# rxflow register map
Vendor: Texas Instruments
Peripheral module from a debugger description file (folder pktdma).
Registers are 32-bit, write-only, no defined reset value unless marked. A register's access mark holds for its fields unless they carry their own. Offsets are as the file gives them; lines under a group give offsets from that group; [hi:lo] are bit positions; {n}, {i} and the like mark numbered series; 'fields as' and 'values as' point back to an identical list; <NAME> marks a mode.

## PKTDMA_RXCHANNEL
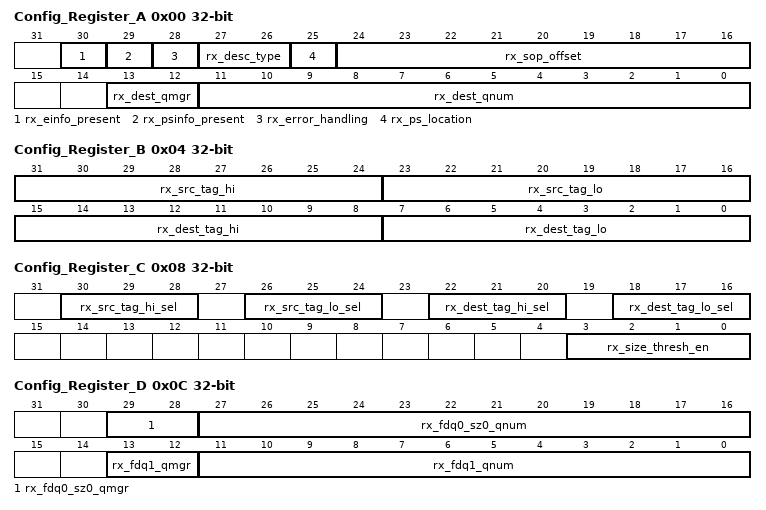
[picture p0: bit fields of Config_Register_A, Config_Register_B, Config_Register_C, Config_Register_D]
0x00 Config_Register_A — RX Flow Configuration Register A
  [30] rx_einfo_present, [29] rx_psinfo_present, [28] rx_error_handling, [27:26] rx_desc_type, [25] rx_ps_location, [24:16] rx_sop_offset, [13:12] rx_dest_qmgr, [11:0] rx_dest_qnum
0x04 Config_Register_B ro — RX Flow Configuration Register B
  [31:24] rx_src_tag_hi, [23:16] rx_src_tag_lo, [15:8] rx_dest_tag_hi, [7:0] rx_dest_tag_lo
0x08 Config_Register_C — RX Flow Configuration Register C
  [30:28] rx_src_tag_hi_sel, [26:24] rx_src_tag_lo_sel, [22:20] rx_dest_tag_hi_sel, [18:16] rx_dest_tag_lo_sel, [3:0] rx_size_thresh_en
0x0C Config_Register_D — RX Flow Configuration Register D
  [29:28] rx_fdq0_sz0_qmgr, [27:16] rx_fdq0_sz0_qnum, [13:12] rx_fdq1_qmgr, [11:0] rx_fdq1_qnum
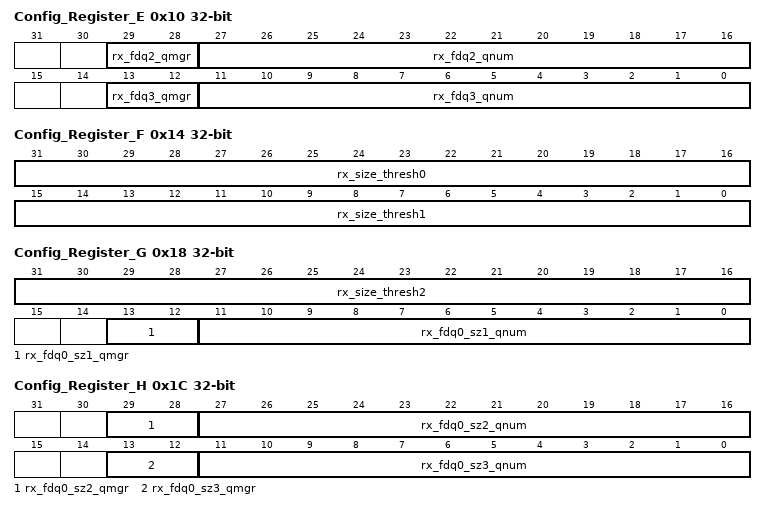
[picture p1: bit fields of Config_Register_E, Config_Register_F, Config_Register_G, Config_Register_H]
0x10 Config_Register_E — RX Flow Configuration Register E
  [29:28] rx_fdq2_qmgr, [27:16] rx_fdq2_qnum, [13:12] rx_fdq3_qmgr, [11:0] rx_fdq3_qnum
0x14 Config_Register_F — RX Flow Configuration Register F
  [31:16] rx_size_thresh0, [15:0] rx_size_thresh1
0x18 Config_Register_G — RX Flow Configuration Register G
  [31:16] rx_size_thresh2, [13:12] rx_fdq0_sz1_qmgr, [11:0] rx_fdq0_sz1_qnum
0x1C Config_Register_H — RX Flow Configuration Register H
  [29:28] rx_fdq0_sz2_qmgr, [27:16] rx_fdq0_sz2_qnum, [13:12] rx_fdq0_sz3_qmgr, [11:0] rx_fdq0_sz3_qnum
